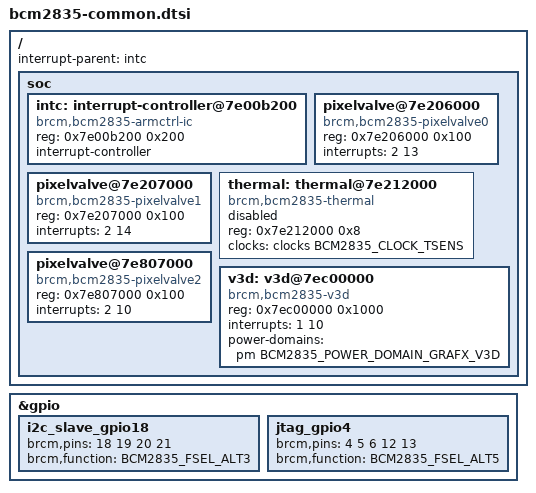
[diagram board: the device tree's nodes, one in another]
// SPDX-License-Identifier: GPL-2.0

/* This include file covers the common peripherals and configuration between
 * bcm2835, bcm2836 and bcm2837 implementations.
 */

/ {
	interrupt-parent = <&intc>;

	soc {
		intc: interrupt-controller@7e00b200 {
			compatible = "brcm,bcm2835-armctrl-ic";
			reg = <0x7e00b200 0x200>;
			interrupt-controller;
			#interrupt-cells = <2>;
		};

		pixelvalve@7e206000 {
			compatible = "brcm,bcm2835-pixelvalve0";
			reg = <0x7e206000 0x100>;
			interrupts = <2 13>; /* pwa0 */
		};

		pixelvalve@7e207000 {
			compatible = "brcm,bcm2835-pixelvalve1";
			reg = <0x7e207000 0x100>;
			interrupts = <2 14>; /* pwa1 */
		};

		thermal: thermal@7e212000 {
			compatible = "brcm,bcm2835-thermal";
			reg = <0x7e212000 0x8>;
			clocks = <&clocks BCM2835_CLOCK_TSENS>;
			#thermal-sensor-cells = <0>;
			status = "disabled";
		};

		pixelvalve@7e807000 {
			compatible = "brcm,bcm2835-pixelvalve2";
			reg = <0x7e807000 0x100>;
			interrupts = <2 10>; /* pixelvalve */
		};

		v3d: v3d@7ec00000 {
			compatible = "brcm,bcm2835-v3d";
			reg = <0x7ec00000 0x1000>;
			interrupts = <1 10>;
			power-domains = <&pm BCM2835_POWER_DOMAIN_GRAFX_V3D>;
		};
	};
};

&gpio {
	i2c_slave_gpio18: i2c_slave_gpio18 {
		brcm,pins = <18 19 20 21>;
		brcm,function = <BCM2835_FSEL_ALT3>;
	};

	jtag_gpio4: jtag_gpio4 {
		brcm,pins = <4 5 6 12 13>;
		brcm,function = <BCM2835_FSEL_ALT5>;
	};
};
